# CC23x0 register map
File version: 1.0
CPU: CM0+ r0p4, little endian, no MPU, no FPU, VTOR, 3 interrupt priority bits
Registers are 32-bit, read-write, reset 0x0 unless marked. A register's access mark holds for its fields unless they carry their own. Offsets are from the block's base; [hi:lo] are bit positions; lines under a group give offsets from that group; {n}, {i} and the like mark numbered series; 'fields as' and 'values as' point back to an identical list.

## GPIO — MCU GPIO - I/F for controlling and reading IO status and IO event status
Base 0x40023000
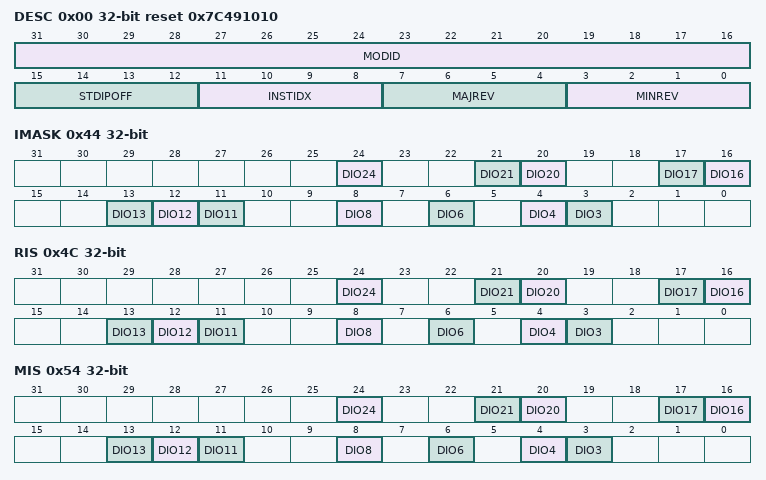
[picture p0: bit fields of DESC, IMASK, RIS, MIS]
0x00 DESC ro reset 0x7C491010 — Provides module ID, revision information, instance index
  [31:16] MODID — Module identifier
    0xFFFF=MAXIMUM (Highest possible value); 0=MINIMUM (Smallest value)
  [15:12] STDIPOFF — 0: STDIP MMRs do not exist 1:15: These MMRs begin at offset 64*STDIPOFF from IP base address
    15=MAXIMUM (Highest possible value); 0=MINIMUM (Smallest value)
  [11:8] INSTIDX — If multiple instances of IP exists in SOC, this field can identify the instance number 0-15
    values as STDIPOFF
  [7:4] MAJREV — Major revision version of IP
    values as STDIPOFF
  [3:0] MINREV — Minor revision version of IP
    values as STDIPOFF
0x04 DESCEX ro reset 0xB — Provide IP-specific instance information
  [5:0] NUMDIO — This provides the total number of DIOs supported by GPIO. The number of DIOs supprted is NUMDIO + 1
    63=MAXIMUM (Highest possible value); 0=MINIMUM (Smallest value)
0x44 IMASK — Interrupt mask for DIO pins
  [all] fields
    1=SET (Set Interrrupt Mask); 0=CLR (Clear Interrupt Mask)
  [24] DIO24 — Interrupt mask for DIO24
  [21] DIO21 — Interrupt mask for DIO21
  [20] DIO20 — Interrupt mask for DIO20
  [17] DIO17 — Interrupt mask for DIO17
  [16] DIO16 — Interrupt mask for DIO16
  [13] DIO13 — Interrupt mask for DIO13
  [12] DIO12 — Interrupt mask for DIO12
  [11] DIO11 — Interrupt mask for DIO11
  [8] DIO8 — Interrupt mask for DIO8
  [6] DIO6 — Interrupt mask for DIO6
  [4] DIO4 — Interrupt mask for DIO4
  [3] DIO3 — Interrupt mask for DIO3
0x4C RIS ro — Raw interrupt flag for DIO pins
  [all] fields
    1=SET (Interrupt occured); 0=CLR (Interrupt did not occur)
  [24] DIO24 — Raw interrupt flag for DIO24
  [21] DIO21 — Raw interrupt flag for DIO21
  [20] DIO20 — Raw interrupt flag for DIO20
  [17] DIO17 — Raw interrupt flag for DIO17
  [16] DIO16 — Raw interrupt flag for DIO16
  [13] DIO13 — Raw interrupt flag for DIO13
  [12] DIO12 — Raw interrupt flag for DIO12
  [11] DIO11 — Raw interrupt flag for DIO11
  [8] DIO8 — Raw interrupt flag for DIO8
  [6] DIO6 — Raw interrupt flag for DIO6
  [4] DIO4 — Raw interrupt flag for DIO4
  [3] DIO3 — Raw interrupt flag for DIO3
0x54 MIS ro — Masked interrupt flag for DIO pins
  [all] fields
    1=SET (Interrupt occured); 0=CLR (Interrupt did not occur)
  [24] DIO24 — Masked interrupt flag for DIO24
  [21] DIO21 — Masked interrupt flag for DIO21
  [20] DIO20 — Masked interrupt flag for DIO20
  [17] DIO17 — Masked interrupt flag for DIO17
  [16] DIO16 — Masked interrupt flag for DIO16
  [13] DIO13 — Masked interrupt flag for DIO13
  [12] DIO12 — Masked interrupt flag for DIO12
  [11] DIO11 — Masked interrupt flag for DIO11
  [8] DIO8 — Masked interrupt flag for DIO8
  [6] DIO6 — Masked interrupt flag for DIO6
  [4] DIO4 — Masked interrupt flag for DIO4
  [3] DIO3 — Masked interrupt flag for DIO3
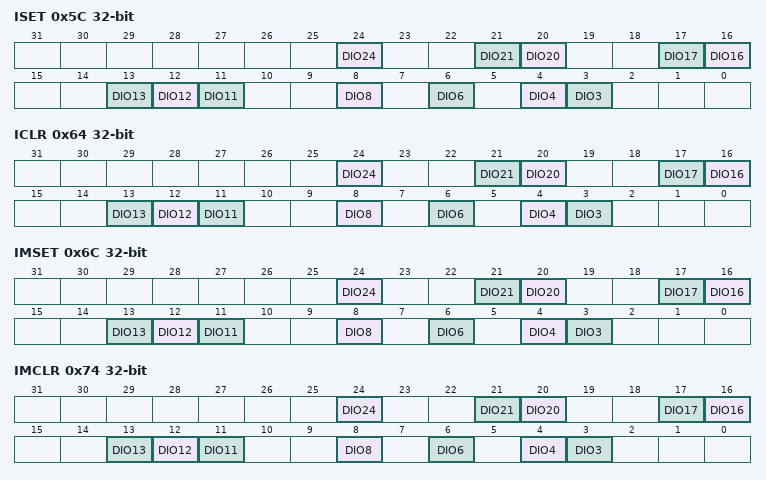
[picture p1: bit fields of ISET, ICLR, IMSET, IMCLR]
0x5C ISET wo — Set interrupt flag in RIS by writing a one
  [all] fields
    1=SET (Set Interrupt); 0=NO_EFFECT (Writing 0 has no effect)
  [24] DIO24 — Set DIO24 in RIS
  [21] DIO21 — Set DIO21 in RIS
  [20] DIO20 — Set DIO20 in RIS
  [17] DIO17 — Set DIO17 in RIS
  [16] DIO16 — Set DIO16 in RIS
  [13] DIO13 — Set DIO13 in RIS
  [12] DIO12 — Set DIO12 in RIS
  [11] DIO11 — Set DIO11 in RIS
  [8] DIO8 — Set DIO8 in RIS
  [6] DIO6 — Set DIO6 in RIS
  [4] DIO4 — Set DIO4 in RIS
  [3] DIO3 — Set DIO3 in RIS
0x64 ICLR wo — Clear interrupt flag in RIS by writing a one
  [all] fields
    1=CLR (Clear Interrupt); 0=NO_EFFECT (Writing 0 has no effect)
  [24] DIO24 — Clears DIO24 in RIS
  [21] DIO21 — Clears DIO21 in RIS
  [20] DIO20 — Clears DIO20 in RIS
  [17] DIO17 — Clears DIO17 in RIS
  [16] DIO16 — Clears DIO16 in RIS
  [13] DIO13 — Clears DIO13 in RIS
  [12] DIO12 — Clears DIO12 in RIS
  [11] DIO11 — Clears DIO11 in RIS
  [8] DIO8 — Clears DIO8 in RIS
  [6] DIO6 — Clears DIO6 in RIS
  [4] DIO4 — Clears DIO4 in RIS
  [3] DIO3 — Clears DIO3 in RIS
0x6C IMSET wo — Set interrupt mask in IMASK by writing a one
  [all] fields
    1=SET (Set interrupt mask); 0=NO_EFFECT (Writing 0 has no effect)
  [24] DIO24 — Sets DIO24 in IMASK
  [21] DIO21 — Sets DIO21 in IMASK
  [20] DIO20 — Sets DIO20 in IMASK
  [17] DIO17 — Sets DIO17 in IMASK
  [16] DIO16 — Sets DIO16 in IMASK
  [13] DIO13 — Sets DIO13 in IMASK
  [12] DIO12 — Sets DIO12 in IMASK
  [11] DIO11 — Sets DIO11 in IMASK
  [8] DIO8 — Sets DIO8 in IMASK
  [6] DIO6 — Sets DIO6 in IMASK
  [4] DIO4 — Sets DIO4 in IMASK
  [3] DIO3 — Sets DIO3 in IMASK
0x74 IMCLR wo — Clear interrupt mask in IMASK by writing a one
  [all] fields
    1=CLR (Clear interrupt mask); 0=NO_EFFECT (Writing 0 has no effect)
  [24] DIO24 — Clears DIO24 in IMASK
  [21] DIO21 — Clears DIO21 in IMASK
  [20] DIO20 — Clears DIO20 in IMASK
  [17] DIO17 — Clears DIO17 in IMASK
  [16] DIO16 — Clears DIO16 in IMASK
  [13] DIO13 — Clears DIO13 in IMASK
  [12] DIO12 — Clears DIO12 in IMASK
  [11] DIO11 — Clears DIO11 in IMASK
  [8] DIO8 — Clears DIO8 in IMASK
  [6] DIO6 — Clears DIO6 in IMASK
  [4] DIO4 — Clears DIO4 in IMASK
  [3] DIO3 — Clears DIO3 in IMASK
0x7C DTB — Digital test bus mux selection
  [2:0] SEL — DTB MUX select pin value
    {v}=GRP{v} (Selects test group {v}) (v=1..7); 0=DISABLE (DTB output from peripheral is 0x0.)
0x100 DOUT3_0 — Data out 3 to 0. Alias register for byte access to DOUT31_0[3:0] bits.
  [24] DIO3 — Data output for DIO3
    1=ONE (Output is set to 1); 0=ZERO (Output is set to 0)
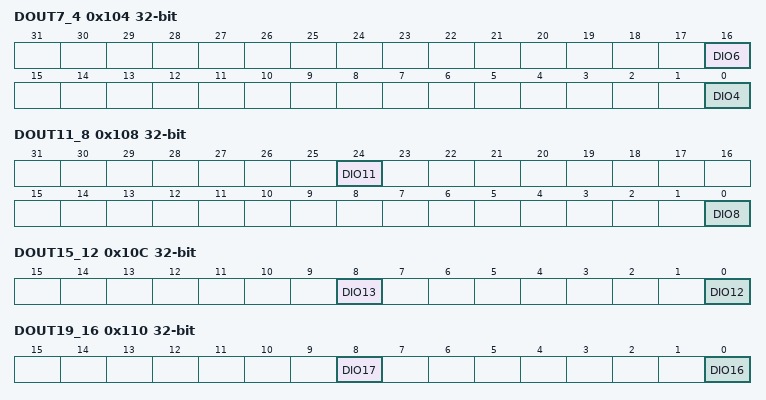
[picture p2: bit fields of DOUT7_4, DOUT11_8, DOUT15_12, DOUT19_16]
0x104 DOUT7_4 — Data out 7 to 4. Alias register for byte access to DOUT31_0[7:4] bits.
  [16] DIO6 — Data output for DIO6
    1=ONE (Output is set to 1); 0=ZERO (Output is set to 0)
  [0] DIO4 — Data output for DIO4
    1=ONE (Output is set to 1); 0=ZERO (Output is set to 0)
0x108 DOUT11_8 — Data out 11 to 8. Alias register for byte access to DOUT31_0[11:8] bits.
  [24] DIO11 — Data output for DIO11
    1=ONE (Output is set to 1); 0=ZERO (Output is set to 0)
  [0] DIO8 — Data output for DIO8
    1=ONE (Output is set to 1); 0=ZERO (Output is set to 0)
0x10C DOUT15_12 — Data out 15 to 12. Alias register for byte access to DOUT31_0[15:12] bits.
  [8] DIO13 — Data output for DIO13
    1=ONE (Output is set to 1); 0=ZERO (Output is set to 0)
  [0] DIO12 — Data output for DIO12
    1=ONE (Output is set to 1); 0=ZERO (Output is set to 0)
0x110 DOUT19_16 — Data out 19 to 16. Alias register for byte access to DOUT31_0[19:16] bits.
  [8] DIO17 — Data output for DIO17
    1=ONE (Output is set to 1); 0=ZERO (Output is set to 0)
  [0] DIO16 — Data output for DIO16
    1=ONE (Output is set to 1); 0=ZERO (Output is set to 0)
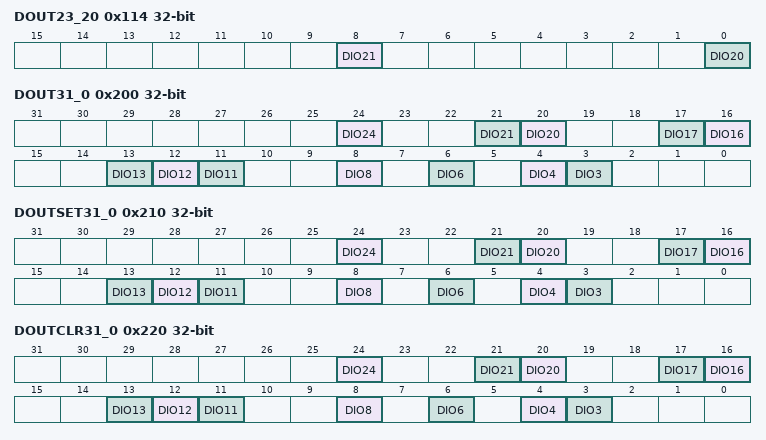
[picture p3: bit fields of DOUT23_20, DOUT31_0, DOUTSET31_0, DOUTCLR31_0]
0x114 DOUT23_20 — Data out 23 to 20. Alias register for byte access to DOUT31_0[23:20] bits.
  [8] DIO21 — Data output for DIO21
    1=ONE (Output is set to 1); 0=ZERO (Output is set to 0)
  [0] DIO20 — Data output for DIO20
    1=ONE (Output is set to 1); 0=ZERO (Output is set to 0)
0x118 DOUT27_24 — Data out 27 to 24. Alias register for byte access to DOUT31_0[27:24] bits.
  [0] DIO24 — Data output for DIO24
    1=ONE (Output is set to 1); 0=ZERO (Output is set to 0)
0x200 DOUT31_0 — Data Output for DIO 31 to 0 pins.
  [all] fields
    1=ONE (Output is set to 1); 0=ZERO (Output is set to 0)
  [24] DIO24 — Data output for DIO24
  [21] DIO21 — Data output for DIO21
  [20] DIO20 — Data output for DIO20
  [17] DIO17 — Data output for DIO17
  [16] DIO16 — Data output for DIO16
  [13] DIO13 — Data output for DIO13
  [12] DIO12 — Data output for DIO12
  [11] DIO11 — Data output for DIO11
  [8] DIO8 — Data output for DIO8
  [6] DIO6 — Data output for DIO6
  [4] DIO4 — Data output for DIO4
  [3] DIO3 — Data output for DIO3
0x210 DOUTSET31_0 wo — Data output set for DIO 31 to 0 pins. Writing 1 to a bit position sets the corresponding bit in the DOUT31_0 register.
  [all] fields
    1=SET; 0=NO_EFFECT
  [24] DIO24 — Set bit DIO24 in DOUT31_0
  [21] DIO21 — Set bit DIO21 in DOUT31_0
  [20] DIO20 — Set bit DIO20 in DOUT31_0
  [17] DIO17 — Set bit DIO17 in DOUT31_0
  [16] DIO16 — Set bit DIO16 in DOUT31_0
  [13] DIO13 — Set bit DIO13 in DOUT31_0
  [12] DIO12 — Set bit DIO12 in DOUT31_0
  [11] DIO11 — Set bit DIO11 in DOUT31_0
  [8] DIO8 — Set bit DIO8 in DOUT31_0
  [6] DIO6 — Set bit DIO6 in DOUT31_0
  [4] DIO4 — Set bit DIO4 in DOUT31_0
  [3] DIO3 — Set bit DIO3 in DOUT31_0
0x220 DOUTCLR31_0 wo — Data output clear for DIO 31 to 0 pins. Writing 1 to a bit position clears the corresponding bit in the DOUT31_0 register.
  [all] fields
    1=CLR (Clear); 0=NO_EFFECT
  [24] DIO24 — Clear bit DIO24 in DOUT31_0
  [21] DIO21 — Clear bit DIO21 in DOUT31_0
  [20] DIO20 — Clear bit DIO20 in DOUT31_0
  [17] DIO17 — Clear bit DIO17 in DOUT31_0
  [16] DIO16 — Clear bit DIO16 in DOUT31_0
  [13] DIO13 — Clear bit DIO13 in DOUT31_0
  [12] DIO12 — Clear bit DIO12 in DOUT31_0
  [11] DIO11 — Clear bit DIO11 in DOUT31_0
  [8] DIO8 — Clear bit DIO8 in DOUT31_0
  [6] DIO6 — Clear bit DIO6 in DOUT31_0
  [4] DIO4 — Clear bit DIO4 in DOUT31_0
  [3] DIO3 — Clear bit DIO3 in DOUT31_0
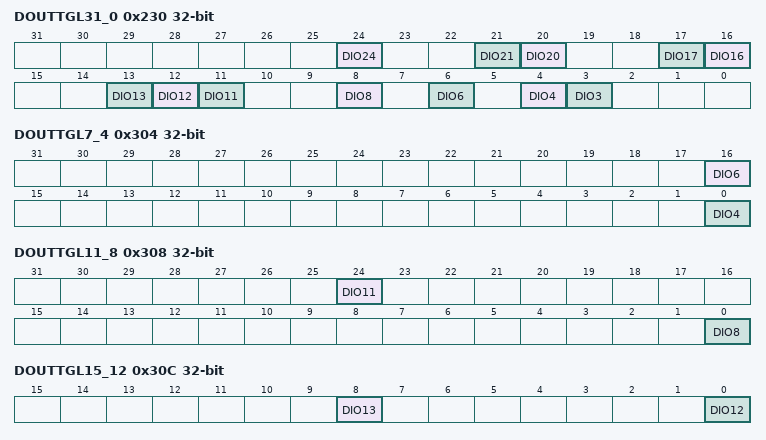
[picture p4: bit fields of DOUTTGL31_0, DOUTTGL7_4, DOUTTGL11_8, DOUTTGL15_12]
0x230 DOUTTGL31_0 wo — Data output toggle for DIO 31 to 0 pins. Writing 1 to a bit position will invert the corresponding bit in DOUT31_0 register.
  [all] fields
    1=TOGGLE; 0=NO_EFFECT
  [24] DIO24 — Toggles bit DIO24 in DOUT31_0
  [21] DIO21 — Toggles bit DIO21 in DOUT31_0
  [20] DIO20 — Toggles bit DIO20 in DOUT31_0
  [17] DIO17 — Toggles bit DIO17 in DOUT31_0
  [16] DIO16 — Toggles bit DIO16 in DOUT31_0
  [13] DIO13 — Toggles bit DIO13 in DOUT31_0
  [12] DIO12 — Toggles bit DIO12 in DOUT31_0
  [11] DIO11 — Toggles bit DIO11 in DOUT31_0
  [8] DIO8 — Toggles bit DIO8 in DOUT31_0
  [6] DIO6 — Toggles bit DIO6 in DOUT31_0
  [4] DIO4 — Toggles bit DIO4 in DOUT31_0
  [3] DIO3 — Toggles bit DIO3 in DOUT31_0
0x300 DOUTTGL3_0 wo — Data out toggle 3 to 0. Alias register for byte access to DOUTTGL31_0[3:0] bits.
  [24] DIO3 — Data output toggle for DIO3
    1=TOGGLE; 0=NO_EFFECT
0x304 DOUTTGL7_4 wo — Data out toggle 7 to 4. Alias register for byte access to DOUTTGL31_0[7:4] bits.
  [16] DIO6 — Data output toggle for DIO6
    1=TOGGLE; 0=NO_EFFECT
  [0] DIO4 — Data output toggle for DIO4
    1=TOGGLE; 0=NO_EFFECT
0x308 DOUTTGL11_8 wo — Data out toggle 11 to 8. Alias register for byte access to DOUTTGL31_0[11:8] bits.
  [24] DIO11 — Data output toggle for DIO11
    1=TOGGLE; 0=NO_EFFECT
  [0] DIO8 — Data output toggle for DIO8
    1=TOGGLE; 0=NO_EFFECT
0x30C DOUTTGL15_12 wo — Data out toggle 15 to 12. Alias register for byte access to DOUTTGL31_0[15:12] bits.
  [8] DIO13 — Data output toggle for DIO13
    1=TOGGLE; 0=NO_EFFECT
  [0] DIO12 — Data output toggle for DIO12
    1=TOGGLE; 0=NO_EFFECT
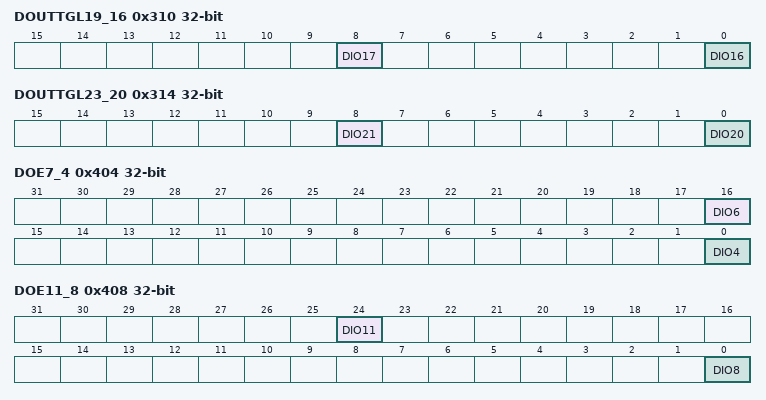
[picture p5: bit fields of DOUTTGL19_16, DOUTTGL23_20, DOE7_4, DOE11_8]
0x310 DOUTTGL19_16 wo — Data out toggle 19 to 16. Alias register for byte access to DOUTTGL31_0[19:16] bits.
  [8] DIO17 — Data output toggle for DIO17
    1=TOGGLE; 0=NO_EFFECT
  [0] DIO16 — Data output toggle for DIO16
    1=TOGGLE; 0=NO_EFFECT
0x314 DOUTTGL23_20 wo — Data out toggle 23 to 20. Alias register for byte access to DOUTTGL31_0[23:20] bits.
  [8] DIO21 — Data output toggle for DIO21
    1=TOGGLE; 0=NO_EFFECT
  [0] DIO20 — Data output toggle for DIO20
    1=TOGGLE; 0=NO_EFFECT
0x318 DOUTTGL27_24 wo — Data out toggle 27 to 24. Alias register for byte access to DOUTTGL31_0[27:24] bits.
  [0] DIO24 — Data output toggle for DIO24
    1=TOGGLE; 0=NO_EFFECT
0x400 DOE3_0 — Data out enable 3 to 0. Alias register for byte access to DOE31_0[3:0] bits.
  [24] DIO3 — Data output enable for DIO3
    1=ENABLE (Output enabled); 0=DISABLE (Output disabled)
0x404 DOE7_4 — Data out enable 7 to 4. Alias register for byte access to DOE31_0[7:4] bits.
  [16] DIO6 — Data output enable for DIO6
    1=ENABLE (Output enabled); 0=DISABLE (Output disabled)
  [0] DIO4 — Data output enable for DIO4
    1=ENABLE (Output enabled); 0=DISABLE (Output disabled)
0x408 DOE11_8 — Data out enable 11 to 8. Alias register for byte access to DOE31_0[11:8] bits.
  [24] DIO11 — Data output enable for DIO11
    1=ENABLE (Output enabled); 0=DISABLE (Output disabled)
  [0] DIO8 — Data output enable for DIO8
    1=ENABLE (Output enabled); 0=DISABLE (Output disabled)
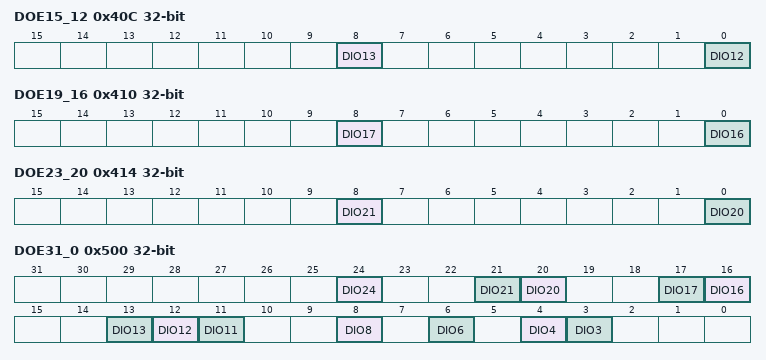
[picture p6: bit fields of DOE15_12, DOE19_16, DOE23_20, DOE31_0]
0x40C DOE15_12 — Data out enable 15 to 12. Alias register for byte access to DOE31_0[15:12] bits.
  [8] DIO13 — Data output enable for DIO13
    1=ENABLE (Output enabled); 0=DISABLE (Output disabled)
  [0] DIO12 — Data output enable for DIO12
    1=ENABLE (Output enabled); 0=DISABLE (Output disabled)
0x410 DOE19_16 — Data out enable 19 to 16. Alias register for byte access to DOE31_0[19:16] bits.
  [8] DIO17 — Data output enable for DIO17
    1=ENABLE (Output enabled); 0=DISABLE (Output disabled)
  [0] DIO16 — Data output enable for DIO16
    1=ENABLE (Output enabled); 0=DISABLE (Output disabled)
0x414 DOE23_20 — Data out enable 23 to 20. Alias register for byte access to DOE31_0[23:20] bits.
  [8] DIO21 — Data output enable for DIO21
    1=ENABLE (Output enabled); 0=DISABLE (Output disabled)
  [0] DIO20 — Data output enable for DIO20
    1=ENABLE (Output enabled); 0=DISABLE (Output disabled)
0x418 DOE27_24 — Data out enable 27 to 24. Alias register for byte access to DOE31_0[27:24] bits.
  [0] DIO24 — Data output enable for DIO24
    1=ENABLE (Output enabled); 0=DISABLE (Output disabled)
0x500 DOE31_0 — Data output enable for DIO 31 to 0 pins.
  [all] fields
    1=ENABLE (Output enabled); 0=DISABLE (Output disabled)
  [24] DIO24 — Data output enable for DIO24
  [21] DIO21 — Data output enable for DIO21
  [20] DIO20 — Data output enable for DIO20
  [17] DIO17 — Data output enable for DIO17
  [16] DIO16 — Data output enable for DIO16
  [13] DIO13 — Data output enable for DIO13
  [12] DIO12 — Data output enable for DIO12
  [11] DIO11 — Data output enable for DIO11
  [8] DIO8 — Data output enable for DIO8
  [6] DIO6 — Data output enable for DIO6
  [4] DIO4 — Data output enable for DIO4
  [3] DIO3 — Data output enable for DIO3
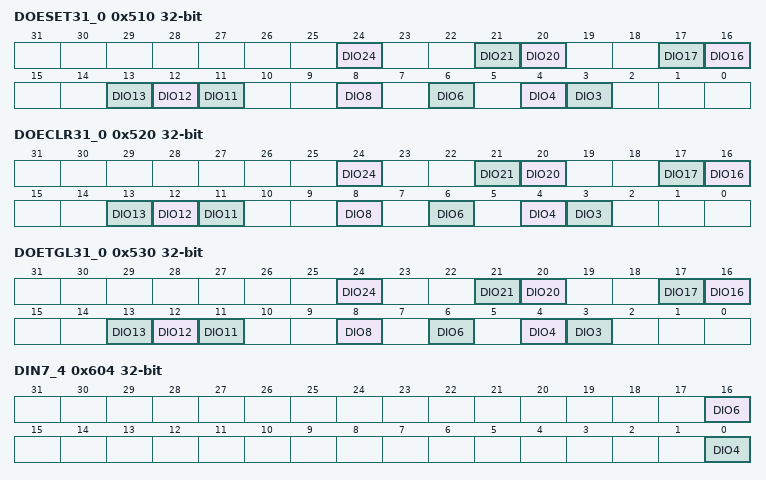
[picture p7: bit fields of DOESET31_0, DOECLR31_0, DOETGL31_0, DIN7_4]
0x510 DOESET31_0 wo — Data output enable set for DIO 31 to 0 pins. Writing 1 to a bit position sets the corresponding bit in the DOE31_0 register.
  [all] fields
    1=SET; 0=NO_EFFECT
  [24] DIO24 — Set bit DIO24 in DOE31_0
  [21] DIO21 — Set bit DIO21 in DOE31_0
  [20] DIO20 — Set bit DIO20 in DOE31_0
  [17] DIO17 — Set bit DIO17 in DOE31_0
  [16] DIO16 — Set bit DIO16 in DOE31_0
  [13] DIO13 — Set bit DIO13 in DOE31_0
  [12] DIO12 — Set bit DIO12 in DOE31_0
  [11] DIO11 — Set bit DIO11 in DOE31_0
  [8] DIO8 — Set bit DIO8 in DOE31_0
  [6] DIO6 — Set bit DIO6 in DOE31_0
  [4] DIO4 — Set bit DIO4 in DOE31_0
  [3] DIO3 — Set bit DIO3 in DOE31_0
0x520 DOECLR31_0 wo — Data output enable clear for DIO 31 to 0 pins. Writing 1 to a bit position clears the corresponding bit in the DOE31_0 register.
  [all] fields
    1=CLR (Clear); 0=NO_EFFECT
  [24] DIO24 — Clears bit DIO24 in DOE31_0
  [21] DIO21 — Clears bit DIO21 in DOE31_0
  [20] DIO20 — Clears bit DIO20 in DOE31_0
  [17] DIO17 — Clears bit DIO17 in DOE31_0
  [16] DIO16 — Clears bit DIO16 in DOE31_0
  [13] DIO13 — Clears bit DIO13 in DOE31_0
  [12] DIO12 — Clears bit DIO12 in DOE31_0
  [11] DIO11 — Clears bit DIO11 in DOE31_0
  [8] DIO8 — Clears bit DIO8 in DOE31_0
  [6] DIO6 — Clears bit DIO6 in DOE31_0
  [4] DIO4 — Clears bit DIO4 in DOE31_0
  [3] DIO3 — Clears bit DIO3 in DOE31_0
0x530 DOETGL31_0 wo — Data output enable toggle for DIO 31 to 0 pins. Writing 1 to a bit position will invert the corresponding bit in DOE31_0 register.
  [all] fields
    1=TOGGLE; 0=NO_EFFECT
  [24] DIO24 — Toggles bit DIO24 in DOE31_0
  [21] DIO21 — Toggles bit DIO21 in DOE31_0
  [20] DIO20 — Toggles bit DIO20 in DOE31_0
  [17] DIO17 — Toggles bit DIO17 in DOE31_0
  [16] DIO16 — Toggles bit DIO16 in DOE31_0
  [13] DIO13 — Toggles bit DIO13 in DOE31_0
  [12] DIO12 — Toggles bit DIO12 in DOE31_0
  [11] DIO11 — Toggles bit DIO11 in DOE31_0
  [8] DIO8 — Toggles bit DIO8 in DOE31_0
  [6] DIO6 — Toggles bit DIO6 in DOE31_0
  [4] DIO4 — Toggles bit DIO4 in DOE31_0
  [3] DIO3 — Toggles bit DIO3 in DOE31_0
0x600 DIN3_0 ro — Data input 3 to 0. Alias register for byte access to DIN31_0[3:0] bits.
  [24] DIO3 — Data input from DIO3
    1=ONE (Input value is 1); 0=ZERO (Input value is 0)
0x604 DIN7_4 ro — Data input 7 to 4. Alias register for byte access to DIN31_0[7:4] bits.
  [16] DIO6 — Data input from DIO6
    1=ONE (Input value is 1); 0=ZERO (Input value is 0)
  [0] DIO4 — Data input from DIO4
    1=ONE (Input value is 1); 0=ZERO (Input value is 0)
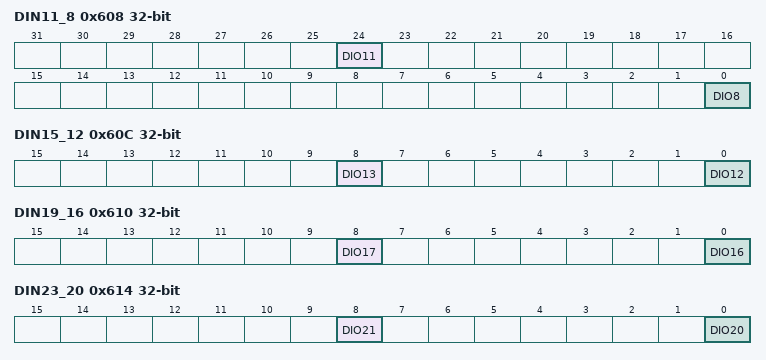
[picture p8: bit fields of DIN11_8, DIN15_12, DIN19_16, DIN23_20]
0x608 DIN11_8 ro — Data input 11 to 8. Alias register for byte access to DIN31_0[11:8] bits.
  [24] DIO11 — Data input from DIO11
    1=ONE (Input value is 1); 0=ZERO (Input value is 0)
  [0] DIO8 — Data input from DIO8
    1=ONE (Input value is 1); 0=ZERO (Input value is 0)
0x60C DIN15_12 ro — Data input 15 to 12. Alias register for byte access to DIN31_0[15:12] bits.
  [8] DIO13 — Data input from DIO13
    1=ONE (Input value is 1); 0=ZERO (Input value is 0)
  [0] DIO12 — Data input from DIO12
    1=ONE (Input value is 1); 0=ZERO (Input value is 0)
0x610 DIN19_16 ro — Data input 19 to 16. Alias register for byte access to DIN31_0[19:16] bits.
  [8] DIO17 — Data input from DIO17
    1=ONE (Input value is 1); 0=ZERO (Input value is 0)
  [0] DIO16 — Data input from DIO16
    1=ONE (Input value is 1); 0=ZERO (Input value is 0)
0x614 DIN23_20 ro — Data input 23 to 20. Alias register for byte access to DIN31_0[23:20] bits.
  [8] DIO21 — Data input from DIO21
    1=ONE (Input value is 1); 0=ZERO (Input value is 0)
  [0] DIO20 — Data input from DIO20
    1=ONE (Input value is 1); 0=ZERO (Input value is 0)
0x618 DIN27_24 ro — Data input 27 to 24. Alias register for byte access to DIN31_0[27:24] bits.
  [0] DIO24 — Data input from DIO24
    1=ONE (Input value is 1); 0=ZERO (Input value is 0)
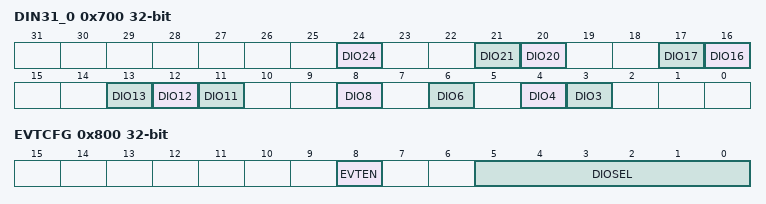
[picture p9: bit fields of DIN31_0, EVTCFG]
0x700 DIN31_0 ro — Data input from DIO 31 to 0 pins.
  [all] fields
    1=ONE (Input value is 1); 0=ZERO (Input value is 0)
  [24] DIO24 — Data input from DIO24
  [21] DIO21 — Data input from DIO21
  [20] DIO20 — Data input from DIO20
  [17] DIO17 — Data input from DIO17
  [16] DIO16 — Data input from DIO16
  [13] DIO13 — Data input from DIO13
  [12] DIO12 — Data input from DIO12
  [11] DIO11 — Data input from DIO11
  [8] DIO8 — Data input from DIO8
  [6] DIO6 — Data input from DIO6
  [4] DIO4 — Data input from DIO4
  [3] DIO3 — Data input from DIO3
0x800 EVTCFG — Event configuration. This register is used to select DIO for GPIO to publish event on SVT event fabric. It also contains enable bit that is used to mask the event.
  [8] EVTEN — Enables GPIO to publish edge qualified selected DIO event on SVT event fabric. Design note: The edge detector flop is cleared automatically for the selected DIO once the event is published.
    1=ENABLE; 0=DISABLE
  [5:0] DIOSEL — This is used to select DIO for event generation. For example, DIOSEL = 0x0 selects DIO0 and DIOSEL = 0x8 selects DIO8.
    63=MAXIMUM (Maximum value); 0=MINIMUM (Minimum value)
